# MSP430FR2355 register map
Vendor: msp430gen; File version: v0.4.0-28-gb0087ce-dirty
Registers are 16-bit, read-write, reset 0x0 unless marked. A register's access mark holds for its fields unless they carry their own. Offsets are from the block's base; [hi:lo] are bit positions; lines under a group give offsets from that group; {n}, {i} and the like mark numbered series.

## SAC0
Base 0x00000C80
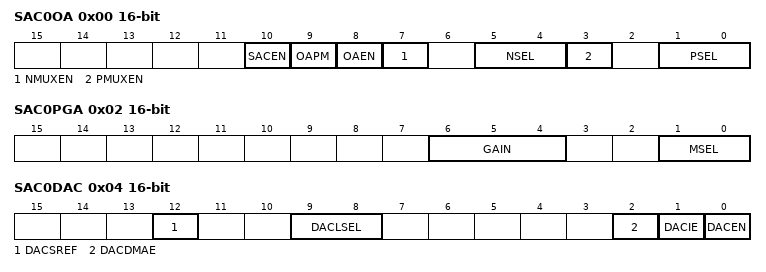
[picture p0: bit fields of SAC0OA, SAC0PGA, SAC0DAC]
0x00 SAC0OA — SAC OA Control Register
  [10] SACEN — SAC Enable selection
    0=SAC all modules are disabled, then the SAC output high impedance; 1=SAC all modules are enabled, normal mode
  [9] OAPM — SAC OA power mode selection
    0=High speed and high power; 1=Llow speed and low power
  [8] OAEN — SAC OA Enable selection
    0=SAC OA is disabled, then the SAC OA output high impedance; 1=SAC OA is enabled, normal mode
  [7] NMUXEN — SAC Negative input MUX controL
    0=All negative input sources are disconnected to OA negative port; 1=All negative input sources are connected to OA negative port
  [5:4] NSEL — SAC OA Negative input source selection
    0=External source selected; 1=PGA source selected; 2=Device Specific
  [3] PMUXEN — SAC Positive input MUX control.
    0=All positive input sources are disconnected to OA positive port; 1=All positive input sources are connected to OA positive port
  [1:0] PSEL — SAC OA Positive input source selection
    0=External source selected; 1=12-bit reference DAC source selected; 2=Pair OA source selected
0x02 SAC0PGA — SAC PGA Control Register
  [6:4] GAIN — SAC PGA Gain configuration
  [1:0] MSEL — SAC PGA Mode Selection
    0=Inverting PGA mode (external pad IN- is selected); 1=Buffer mode (floating is selected ); 2=Non-inverting mode; 3=Cascade OA Inverting mode
0x04 SAC0DAC — SAC DAC Control Register
  [12] DACSREF — SAC DAC select reference voltage
    0=AVCC; 1=Alternative reference
  [9:8] DACLSEL — SAC DAC load select. Selects the load trigger for the DAC latch.
    0=DAC latch loads when DACDAT written; 2=Device specific 0. DAC always loads data from DACDAT at the positive edge of this signal; 3=Device specific 1. DAC always loads data from DACDAT at the positive edge of this signal
  [2] DACDMAE — SAC DAC DMA request enable
    0=DMA request disabled; 1=DMA request enabled
  [1] DACIE — SAC DAC interrupt enable
    0=Disabled; 1=Enabled
  [0] DACEN — SAC DAC enable
    0=Disabled; 1=Enabled
0x06 SAC0DAT — SAC DAC Data Register
  [11:0] DACData — SAC DAC data in unsigned format.
0x08 SAC0DACSTS — SAC DAC Status Register
  [0] DACIFG — SAC DAC data update flag
0x0A SAC0IV — SAC Interrupt Vector Register
  [15:0] SACIV ro
    0=NONE (No interrupt pending); 4=DACIFG (DAC channel update interrupt flag)

## SAC1
Base 0x00000C90
Registers as SAC0 (with SAC0 read as SAC1).

## SAC2
Base 0x00000CA0
Registers as SAC0 (with SAC0 read as SAC2).

## SAC3
Base 0x00000CB0
Registers as SAC0 (with SAC0 read as SAC3).

## TLV — Device descriptors (TLV)
Base 0x00001A00
0x00 INFO_LENGTH 8-bit ro
0x01 CRC_LENGTH 8-bit ro
0x02 CRC_VALUE ro — CRC value of the descriptors from 1A04h to 1AF7h (CRC-CCITT)
0x04 DEVICE_ID ro
{0x4+i} CRC_DATA[{i}] (i=0..243) 8-bit ro — Bytes 1A04h to 1AF7h, the range the CRC value covers
0x06 HW_REVISION 8-bit ro — Hardware revision
0x07 FW_REVISION 8-bit ro — Firmware revision
0x08 DIE_RECORD_TAG 8-bit ro
0x09 DIE_RECORD_LENGTH 8-bit ro
0x0A LOT_WAFER_ID 32-bit ro
0x0E DIE_X_POSITION ro
0x10 DIE_Y_POSITION ro
0x12 TEST_RESULT ro
0x14 ADC_CAL_TAG 8-bit ro — ADC calibration tag
0x15 ADC_CAL_LENGTH 8-bit ro — ADC calibration length
0x16 ADC_GAIN_FACTOR ro
0x18 ADC_OFFSET ro
{0x1A+4i} ADC_TEMP_CAL[{i}] (i=0..2) group — Temperature sensor calibration with the 1.5 V, 2.0 V or 2.5 V reference (index 0, 1 or 2)
  0x00 TEMP_30C ro — Temperature sensor ADC result at 30 degrees C
  0x02 TEMP_HIGH ro — Temperature sensor ADC result at 105 degrees C
0x26 REF_CAL_TAG 8-bit ro — REF calibration tag
0x27 REF_CAL_LENGTH 8-bit ro — REF calibration length
{0x28+2i} REF_FACTOR[{i}] (i=0..2) ro — Factor of the 1.5 V, 2.0 V or 2.5 V reference (index 0, 1 or 2)
0x2E DCO_TAP_16MHZ ro — DCO tap setting for 16 MHz
0x30 DCO_TAP_24MHZ ro — DCO tap setting for 24 MHz
